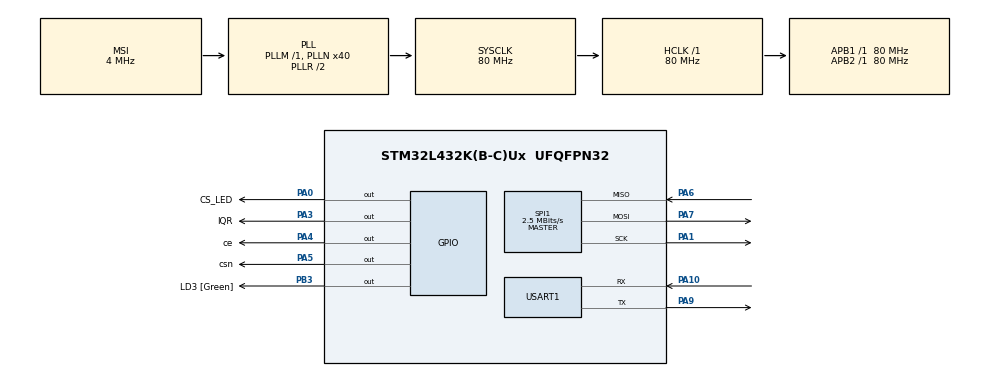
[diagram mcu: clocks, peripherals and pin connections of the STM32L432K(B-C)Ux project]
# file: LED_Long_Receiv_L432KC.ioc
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Mcu.Family=STM32L4
Mcu.Name=STM32L432K(B-C)Ux
Mcu.Package=UFQFPN32
NVIC.PriorityGroup=NVIC_PRIORITYGROUP_4
PA0.GPIO_Label=CS_LED
PA0.PinState=GPIO_PIN_SET
PA0.Signal=GPIO_Output
PA1.Mode=Full_Duplex_Master
PA1.Signal=SPI1_SCK
PA10.Mode=Asynchronous
PA10.Signal=USART1_RX
PA13\ (JTMS-SWDIO).GPIO_Label=SWDIO
PA13\ (JTMS-SWDIO).Mode=Serial_Wire
PA13\ (JTMS-SWDIO).Signal=SYS_JTMS-SWDIO
PA14\ (JTCK-SWCLK).GPIO_Label=SWCLK
PA14\ (JTCK-SWCLK).Mode=Serial_Wire
PA14\ (JTCK-SWCLK).Signal=SYS_JTCK-SWCLK
PA15\ (JTDI).GPIO_Label=VCP_RX
PA15\ (JTDI).Signal=USART2_RX
PA2.GPIO_Label=VCP_TX
PA2.Signal=USART2_TX
PA3.GPIO_Label=IQR
PA3.Signal=GPIO_Output
PA4.GPIO_Label=ce
PA4.PinState=GPIO_PIN_SET
PA4.Signal=GPIO_Output
PA5.GPIO_Label=csn
PA5.PinState=GPIO_PIN_SET
PA5.Signal=GPIO_Output
PA6.Mode=Full_Duplex_Master
PA6.Signal=SPI1_MISO
PA7.Mode=Full_Duplex_Master
PA7.Signal=SPI1_MOSI
PA9.Mode=Asynchronous
PA9.Signal=USART1_TX
PB3\ (JTDO-TRACESWO).GPIO_Label=LD3 [Green]
PB3\ (JTDO-TRACESWO).Signal=GPIO_Output
PC14-OSC32_IN\ (PC14).Mode=LSE-External-Oscillator
PC14-OSC32_IN\ (PC14).Signal=RCC_OSC32_IN
PC15-OSC32_OUT\ (PC15).Mode=LSE-External-Oscillator
PC15-OSC32_OUT\ (PC15).Signal=RCC_OSC32_OUT
ProjectManager.HeapSize=0x200
ProjectManager.StackSize=0x400
ProjectManager.TargetToolchain=STM32CubeIDE
RCC.AHBFreq_Value=80000000
RCC.APB1Freq_Value=80000000
RCC.APB1TimFreq_Value=80000000
RCC.APB2Freq_Value=80000000
RCC.APB2TimFreq_Value=80000000
RCC.CortexFreq_Value=80000000
RCC.HCLKFreq_Value=80000000
RCC.HSE_VALUE=8000000
RCC.HSI16_VALUE=16000000
RCC.HSI48_VALUE=48000000
RCC.HSI_VALUE=16000000
RCC.MSI_VALUE=4000000
RCC.PLLMUL=RCC_PLLMUL_4
RCC.PLLN=40
RCC.SYSCLKFreq_VALUE=80000000
RCC.SYSCLKSource=RCC_SYSCLKSOURCE_PLLCLK
RCC.VCOOutputFreq_Value=160000000
SPI1.BaudRatePrescaler=SPI_BAUDRATEPRESCALER_32
SPI1.CalculateBaudRate=2.5 MBits/s
SPI1.DataSize=SPI_DATASIZE_8BIT
SPI1.Direction=SPI_DIRECTION_2LINES
SPI1.Mode=SPI_MODE_MASTER
SPI1.VirtualType=VM_MASTER
USART1.VirtualMode-Asynchronous=VM_ASYNC
board=NUCLEO-L432KC

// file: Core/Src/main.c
/* USER CODE BEGIN Header */
/**
  ******************************************************************************
  * @file           : main.c
  * @brief          : Main program body
  ******************************************************************************
  * @attention
  *
  * Copyright (c) 2025 STMicroelectronics.
  * All rights reserved.
  *
  * This software is licensed under terms that can be found in the LICENSE file
  * in the root directory of this software component.
  * If no LICENSE file comes with this software, it is provided AS-IS.
  *
  ******************************************************************************
  */
#include <string.h>
#include <stdint.h>
#include <stdio.h>
#include "NRF24_conf.h"
#include "NRF24_reg_addresses.h"
#include "NRF24.h"
#include "main.h"

SPI_HandleTypeDef hspi1;

UART_HandleTypeDef huart1;

/* LED SPI Control */
#define OFF_LED_EXT 0x00
#define BLUE_LED_EXT 0x01
#define YELLOW_LED_EXT 0x02
#define GREEN_LED_EXT 0x04
#define RED_LED_EXT 0x08

/* nRF24L01+ SPI Control */
uint8_t tx_addr[5] = {0x45, 0x55, 0x67, 0x10, 0x21};
uint16_t data = 0;

#define PLD_S 32
uint8_t dataR[PLD_S];
char colorMsg[PLD_S];
char msgToSend[PLD_S];

int red_count = 0;
int green_count = 0;
int blue_count = 0;
int yellow_count = 0;
int off_count = 0;
int all_count = 0;
                          //
void SystemClock_Config(void);
static void MX_GPIO_Init(void);
static void MX_SPI1_Init(void);
static void MX_USART1_UART_Init(void);
void nrf24_setup(void);
void shift_register_send(uint8_t data);

int main(void)
{

  /* MCU Configuration--------------------------------------------------------*/

  /* Reset of all peripherals, Initializes the Flash interface and the Systick. */
  HAL_Init();

  /* Configure the system clock */
  SystemClock_Config();

  /* Initialize all configured peripherals */
  MX_GPIO_Init();
  MX_SPI1_Init();
  MX_USART1_UART_Init();
  /* USER CODE BEGIN 2 */
  //  Set up NRF24L01
  shift_register_send(OFF_LED_EXT); // Only LED A ON
  HAL_Delay(500);
  shift_register_send(BLUE_LED_EXT); // Only LED A ON

  nrf24_setup();

  shift_register_send(OFF_LED_EXT); // Only LED A ON
  HAL_Delay(500);

  /* USER CODE END 2 */

  /* Infinite loop */
  /* USER CODE BEGIN WHILE */
  while (1)
  {
      uint8_t dataR[PLD_S];
      char colorMsg[PLD_S];
      nrf24_listen();

      if(nrf24_data_available())
      {
          HAL_GPIO_WritePin(LD3_GPIO_Port, LD3_Pin, GPIO_PIN_SET);
          nrf24_receive(dataR, sizeof(dataR));
          // Copy received data to colorMsg and ensure null-termination
          strncpy(colorMsg, (char *)dataR, PLD_S);
          colorMsg[PLD_S - 1] = '\0';
          // Remove trailing newline if present
          size_t len = strlen(colorMsg);
          if (len > 0 && colorMsg[len - 1] == '\n')
          {
              colorMsg[len - 1] = '\0';
          }
          // Compare full color name
          if (strcmp(colorMsg, "red") == 0)
          {
              red_count++;
        	  shift_register_send(RED_LED_EXT);
          }
          else if (strcmp(colorMsg, "green") == 0)
          {
              green_count++;
        	  shift_register_send(GREEN_LED_EXT);
          }
          else if (strcmp(colorMsg, "blue") == 0)
          {
              blue_count++;
        	  shift_register_send(BLUE_LED_EXT);
          }
          else if (strcmp(colorMsg, "yellow") == 0)
          {
              yellow_count++;
        	  shift_register_send(YELLOW_LED_EXT);
          }
          else if (strcmp(colorMsg, "off") == 0)
          {
              off_count++;
        	  shift_register_send(OFF_LED_EXT);
          }
          else if (strcmp(colorMsg, "all") == 0)
          {
        	  all_count++;
              shift_register_send(BLUE_LED_EXT | RED_LED_EXT | GREEN_LED_EXT | YELLOW_LED_EXT);
          }
          else if (strcmp(colorMsg, "count") == 0)
		  {
        	  memset(msgToSend, 0, sizeof(msgToSend)); // Fill with nulls
        	  snprintf(msgToSend, sizeof(msgToSend), "CC,%d,%d,%d,%d,%d,%d", red_count, green_count, blue_count, yellow_count, off_count, all_count);
        	  // msgToSend is now 32 bytes, padded with nulls if the formatted string is shorter
        	  nrf24_stop_listen();
//        	  HAL_Delay(100); // Short delay to ensure the nRF24L01+ is ready
        	  nrf24_transmit(msgToSend, sizeof(msgToSend));
//        	  HAL_Delay(100); // Short delay to ensure the nRF24L01+ is ready

		  }
		  else
		  {
			  // Unknown color command, turn off all LEDs
			  shift_register_send(OFF_LED_EXT);
		  }

          HAL_Delay(1000);
      }
      else
      {
          HAL_GPIO_WritePin(LD3_GPIO_Port, LD3_Pin, GPIO_PIN_RESET);
          HAL_Delay(1000);
      }

      HAL_Delay(100);

  }

}/* End of  main() */

void number_to_string(uint16_t number, char* str, size_t str_size)
{
	snprintf(str, str_size, "%u", number);
}

void shift_register_send(uint8_t data)
{
	HAL_GPIO_WritePin(CS_LED_GPIO_Port, CS_LED_Pin, GPIO_PIN_RESET);
	HAL_SPI_Transmit(&hspi1, &data, 1, HAL_MAX_DELAY);
	HAL_GPIO_WritePin(CS_LED_GPIO_Port, CS_LED_Pin, GPIO_PIN_SET);
}

void nrf24_setup(void)
{
	// Add your NRF24L01 setup code here if needed
	  ce_high();

	  HAL_Delay(5);

	  ce_low();

	  nrf24_init();

	  nrf24_stop_listen();

	  nrf24_auto_ack_all(auto_ack);
	  nrf24_en_ack_pld(disable);
	  nrf24_dpl(disable);

	  nrf24_set_crc(no_crc, _1byte);

	  nrf24_tx_pwr(_0dbm);
	  nrf24_data_rate(_1mbps);
	  nrf24_set_channel(90);
	  nrf24_set_addr_width(5);

	  nrf24_set_rx_dpl(0, disable);
	  nrf24_set_rx_dpl(1, disable);
	  nrf24_set_rx_dpl(2, disable);
	  nrf24_set_rx_dpl(3, disable);
	  nrf24_set_rx_dpl(4, disable);
	  nrf24_set_rx_dpl(5, disable);

	  nrf24_pipe_pld_size(0, PLD_S);

	  nrf24_auto_retr_delay(4);
	  nrf24_auto_retr_limit(10);

	  nrf24_open_tx_pipe(tx_addr);
	  nrf24_open_rx_pipe(0, tx_addr);
	  ce_high();

}

void SystemClock_Config(void)
{
  RCC_OscInitTypeDef RCC_OscInitStruct = {0};
  RCC_ClkInitTypeDef RCC_ClkInitStruct = {0};

  /** Configure the main internal regulator output voltage
  */
  if (HAL_PWREx_ControlVoltageScaling(PWR_REGULATOR_VOLTAGE_SCALE1) != HAL_OK)
  {
    Error_Handler();
  }

  /** Configure LSE Drive Capability
  */
  HAL_PWR_EnableBkUpAccess();
  __HAL_RCC_LSEDRIVE_CONFIG(RCC_LSEDRIVE_LOW);

  /** Initializes the RCC Oscillators according to the specified parameters
  * in the RCC_OscInitTypeDef structure.
  */
  RCC_OscInitStruct.OscillatorType = RCC_OSCILLATORTYPE_LSE|RCC_OSCILLATORTYPE_MSI;
  RCC_OscInitStruct.LSEState = RCC_LSE_ON;
  RCC_OscInitStruct.MSIState = RCC_MSI_ON;
  RCC_OscInitStruct.MSICalibrationValue = 0;
  RCC_OscInitStruct.MSIClockRange = RCC_MSIRANGE_6;
  RCC_OscInitStruct.PLL.PLLState = RCC_PLL_ON;
  RCC_OscInitStruct.PLL.PLLSource = RCC_PLLSOURCE_MSI;
  RCC_OscInitStruct.PLL.PLLM = 1;
  RCC_OscInitStruct.PLL.PLLN = 40;
  RCC_OscInitStruct.PLL.PLLP = RCC_PLLP_DIV7;
  RCC_OscInitStruct.PLL.PLLQ = RCC_PLLQ_DIV2;
  RCC_OscInitStruct.PLL.PLLR = RCC_PLLR_DIV2;
  if (HAL_RCC_OscConfig(&RCC_OscInitStruct) != HAL_OK)
  {
    Error_Handler();
  }

  /** Initializes the CPU, AHB and APB buses clocks
  */
  RCC_ClkInitStruct.ClockType = RCC_CLOCKTYPE_HCLK|RCC_CLOCKTYPE_SYSCLK
                              |RCC_CLOCKTYPE_PCLK1|RCC_CLOCKTYPE_PCLK2;
  RCC_ClkInitStruct.SYSCLKSource = RCC_SYSCLKSOURCE_PLLCLK;
  RCC_ClkInitStruct.AHBCLKDivider = RCC_SYSCLK_DIV1;
  RCC_ClkInitStruct.APB1CLKDivider = RCC_HCLK_DIV1;
  RCC_ClkInitStruct.APB2CLKDivider = RCC_HCLK_DIV1;

  if (HAL_RCC_ClockConfig(&RCC_ClkInitStruct, FLASH_LATENCY_4) != HAL_OK)
  {
    Error_Handler();
  }

  /** Enable MSI Auto calibration
  */
  HAL_RCCEx_EnableMSIPLLMode();
}

static void MX_SPI1_Init(void)
{

  /* SPI1 parameter configuration*/
  hspi1.Instance = SPI1;
  hspi1.Init.Mode = SPI_MODE_MASTER;
  hspi1.Init.Direction = SPI_DIRECTION_2LINES;
  hspi1.Init.DataSize = SPI_DATASIZE_8BIT;
  hspi1.Init.CLKPolarity = SPI_POLARITY_LOW;
  hspi1.Init.CLKPhase = SPI_PHASE_1EDGE;
  hspi1.Init.NSS = SPI_NSS_SOFT;
  hspi1.Init.BaudRatePrescaler = SPI_BAUDRATEPRESCALER_32;
  hspi1.Init.FirstBit = SPI_FIRSTBIT_MSB;
  hspi1.Init.TIMode = SPI_TIMODE_DISABLE;
  hspi1.Init.CRCCalculation = SPI_CRCCALCULATION_DISABLE;
  hspi1.Init.CRCPolynomial = 7;
  hspi1.Init.CRCLength = SPI_CRC_LENGTH_DATASIZE;
  hspi1.Init.NSSPMode = SPI_NSS_PULSE_ENABLE;
  if (HAL_SPI_Init(&hspi1) != HAL_OK)
  {
    Error_Handler();
  }

}

static void MX_USART1_UART_Init(void)
{

  huart1.Instance = USART1;
  huart1.Init.BaudRate = 115200;
  huart1.Init.WordLength = UART_WORDLENGTH_8B;
  huart1.Init.StopBits = UART_STOPBITS_1;
  huart1.Init.Parity = UART_PARITY_NONE;
  huart1.Init.Mode = UART_MODE_TX_RX;
  huart1.Init.HwFlowCtl = UART_HWCONTROL_NONE;
  huart1.Init.OverSampling = UART_OVERSAMPLING_16;
  huart1.Init.OneBitSampling = UART_ONE_BIT_SAMPLE_DISABLE;
  huart1.AdvancedInit.AdvFeatureInit = UART_ADVFEATURE_NO_INIT;
  if (HAL_UART_Init(&huart1) != HAL_OK)
  {
    Error_Handler();
  }

}

static void MX_GPIO_Init(void)
{
  GPIO_InitTypeDef GPIO_InitStruct = {0};

  /* GPIO Ports Clock Enable */
  __HAL_RCC_GPIOC_CLK_ENABLE();
  __HAL_RCC_GPIOA_CLK_ENABLE();
  __HAL_RCC_GPIOB_CLK_ENABLE();

  /*Configure GPIO pin Output Level */
  HAL_GPIO_WritePin(GPIOA, CS_LED_Pin|ce_Pin|csn_Pin, GPIO_PIN_SET);

  /*Configure GPIO pin Output Level */
  HAL_GPIO_WritePin(IQR_GPIO_Port, IQR_Pin, GPIO_PIN_RESET);

  /*Configure GPIO pin Output Level */
  HAL_GPIO_WritePin(LD3_GPIO_Port, LD3_Pin, GPIO_PIN_RESET);

  /*Configure GPIO pins : CS_LED_Pin IQR_Pin ce_Pin csn_Pin */
  GPIO_InitStruct.Pin = CS_LED_Pin|IQR_Pin|ce_Pin|csn_Pin;
  GPIO_InitStruct.Mode = GPIO_MODE_OUTPUT_PP;
  GPIO_InitStruct.Pull = GPIO_NOPULL;
  GPIO_InitStruct.Speed = GPIO_SPEED_FREQ_LOW;
  HAL_GPIO_Init(GPIOA, &GPIO_InitStruct);

  /*Configure GPIO pin : VCP_TX_Pin */
  GPIO_InitStruct.Pin = VCP_TX_Pin;
  GPIO_InitStruct.Mode = GPIO_MODE_AF_PP;
  GPIO_InitStruct.Pull = GPIO_NOPULL;
  GPIO_InitStruct.Speed = GPIO_SPEED_FREQ_VERY_HIGH;
  GPIO_InitStruct.Alternate = GPIO_AF7_USART2;
  HAL_GPIO_Init(VCP_TX_GPIO_Port, &GPIO_InitStruct);

  /*Configure GPIO pin : VCP_RX_Pin */
  GPIO_InitStruct.Pin = VCP_RX_Pin;
  GPIO_InitStruct.Mode = GPIO_MODE_AF_PP;
  GPIO_InitStruct.Pull = GPIO_NOPULL;
  GPIO_InitStruct.Speed = GPIO_SPEED_FREQ_VERY_HIGH;
  GPIO_InitStruct.Alternate = GPIO_AF3_USART2;
  HAL_GPIO_Init(VCP_RX_GPIO_Port, &GPIO_InitStruct);

  /*Configure GPIO pin : LD3_Pin */
  GPIO_InitStruct.Pin = LD3_Pin;
  GPIO_InitStruct.Mode = GPIO_MODE_OUTPUT_PP;
  GPIO_InitStruct.Pull = GPIO_NOPULL;
  GPIO_InitStruct.Speed = GPIO_SPEED_FREQ_LOW;
  HAL_GPIO_Init(LD3_GPIO_Port, &GPIO_InitStruct);

}

void Error_Handler(void)
{
  __disable_irq();
  while (1)
  {
  }
}
